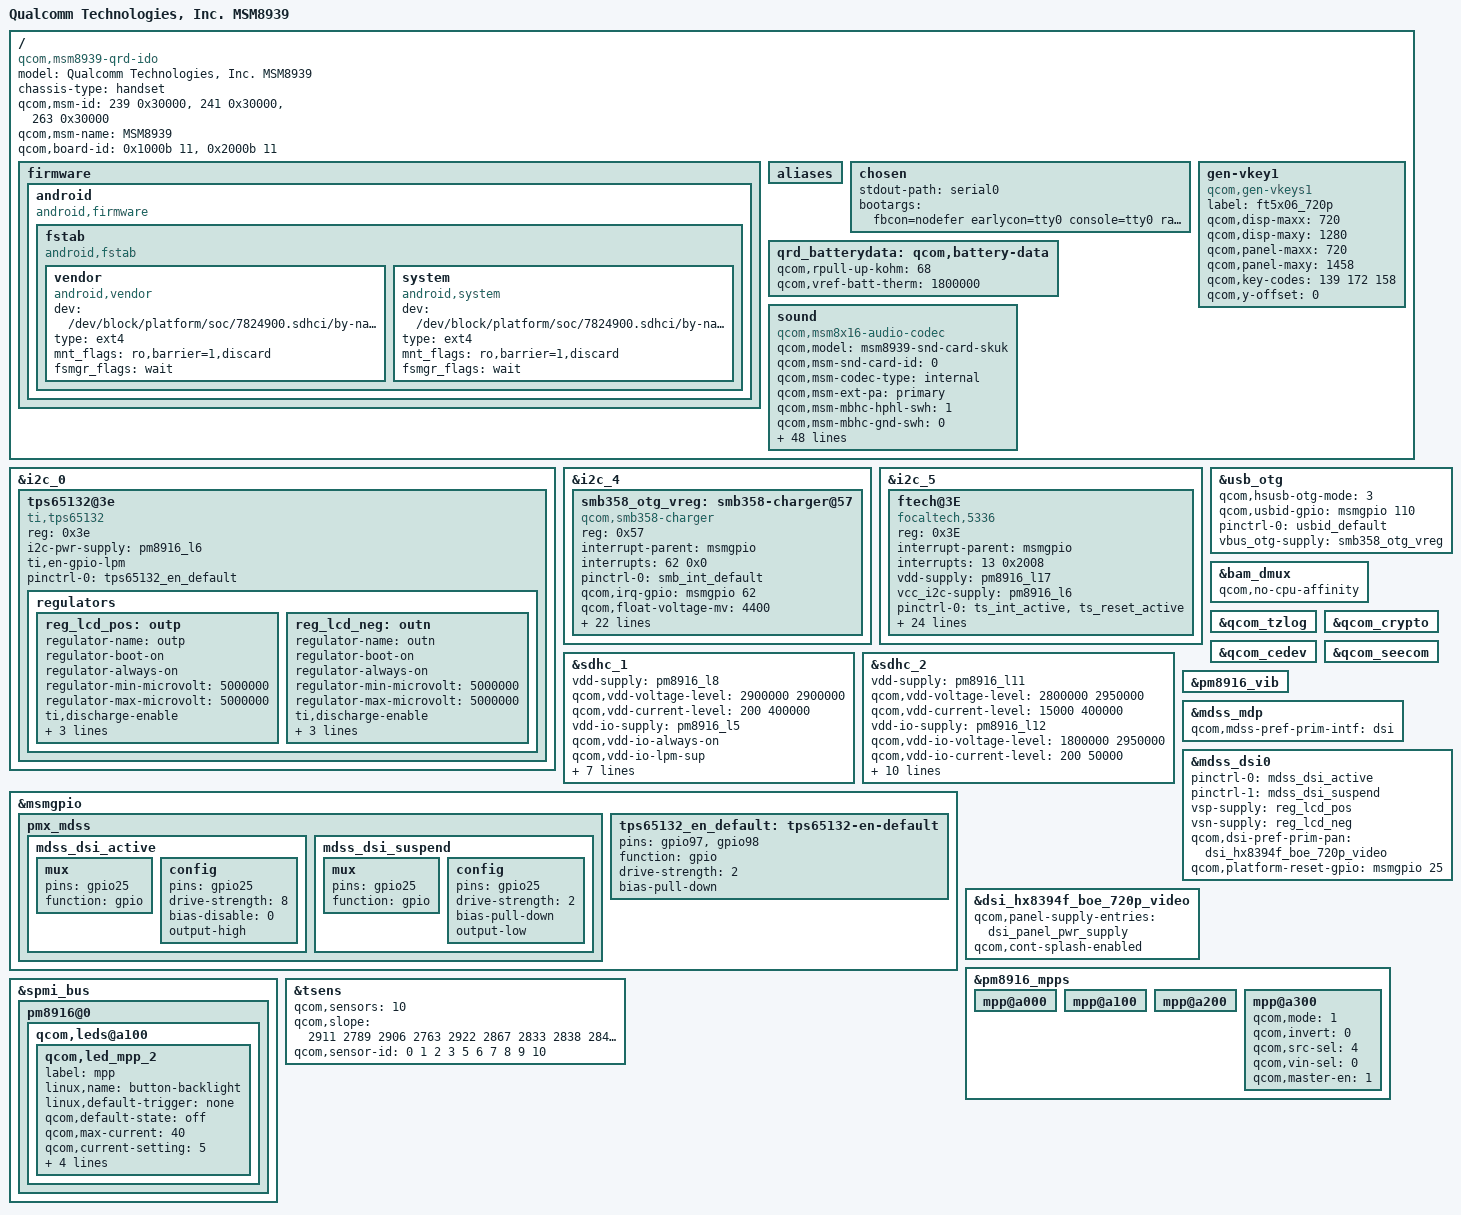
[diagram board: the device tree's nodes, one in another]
// SPDX-License-Identifier: GPL-2.0-only

/dts-v1/;
#include <dt-bindings/clock/msm-clocks-8936.h>
#include <dt-bindings/clock/msm-cpu-clocks-8939.h>
#include "msm8939.dtsi"
#include "msm8939-camera-sensor-qrd-ido.dtsi"
#include "dsi-panel-hx8394f-boe-720p-video.dtsi"
#include <dt-bindings/gpio/gpio.h>

/ {
	model = "Qualcomm Technologies, Inc. MSM8939";
	compatible = "qcom,msm8939-qrd-ido", "qcom,msm8939-qrd", "qcom,msm8939", "qcom,qrd";
	chassis-type = "handset";
	qcom,msm-id = <239 0x30000>, <241 0x30000>, <263 0x30000>;
	qcom,msm-name = "MSM8939";
	qcom,board-id = <0x1000b 11>, <0x2000b 11>;

       firmware: firmware {
                 android {
                         compatible = "android,firmware";
                         fstab {
                                 compatible = "android,fstab";
                                 vendor {
                                         compatible = "android,vendor";
                                         dev = "/dev/block/platform/soc/7824900.sdhci/by-name/vendor";
                                         type = "ext4";
                                         mnt_flags = "ro,barrier=1,discard";
                                         fsmgr_flags = "wait";
                                         status = "ok";
                                 };
                                 system {
                                         compatible = "android,system";
                                         dev = "/dev/block/platform/soc/7824900.sdhci/by-name/system";
                                        type = "ext4";
                                     mnt_flags = "ro,barrier=1,discard";
                                       fsmgr_flags = "wait";
                                      status = "ok";
                                 };
                        };
                };
       };

	aliases {
	};

	chosen {
		stdout-path = "serial0";
		bootargs = "fbcon=nodefer earlycon=tty0 console=tty0 ramoops.mem_address=0xdfe00000 ramoops.mem_size=0x00200000 ramoops.record_size=0x40000 ramoops.console_size=0x40000 ramoops.ftrace_size=0x10000 ramoops.pmsg_size=0x20000 ramoops.ecc=1";
		#address-cells = <2>;
		#size-cells = <2>;
		ranges;
#if 0
		framebuffer0: framebuffer@83003000 {
			status= "okay";
			compatible = "simple-framebuffer";
			reg = <0x0 0x83200000 0x0 0x2000000>;
			width = <720>;
			height = <1280>;
			stride = <(720 * 3)>;
			format = "r8g8b8";
		};
#endif
	};
#if 0
    reserved-memory {
		cont_splash_mem: framebuffer@83000000 {
			compatible = "removed-dma-pool";
			reg = <0x0 0x83000000 0x0 0x2000000>;
			no-map;
		};
	};
#endif

	qrd_batterydata: qcom,battery-data {
		qcom,rpull-up-kohm = <68>;
		qcom,vref-batt-therm = <1800000>;

		#include "batterydata-wingtech-xingwangda_ATL-4v4-4000mah.dtsi"
	};

	gen-vkey1 {
		compatible = "qcom,gen-vkeys1";
		label = "ft5x06_720p";
		qcom,disp-maxx = <720>;
		qcom,disp-maxy = <1280>;
		qcom,panel-maxx = <720>;
		qcom,panel-maxy = <1458>;
		qcom,key-codes = <139 172 158>;
		qcom,y-offset = <0>;
	};

	sound {
		compatible = "qcom,msm8x16-audio-codec";
		qcom,model = "msm8939-snd-card-skuk";
		qcom,msm-snd-card-id = <0>;
		qcom,msm-codec-type = "internal";
		qcom,msm-ext-pa = "primary";
		qcom,msm-mbhc-hphl-swh = <1>;
		qcom,msm-mbhc-gnd-swh = <0>;
		ext-spk-amp-gpio = <&msmgpio 121 0>;
		headset-gpio = <&msmgpio 8 0>;
		qcom,msm-micbias1-ext-cap;
		qcom,msm-hs-micbias-type = "internal";
		qcom,audio-routing =
			"RX_BIAS","MCLK",
			"SPK_RX_BIAS","MCLK",
			"INT_LDO_H","MCLK",
			"MIC BIAS External","Handset Mic",
			"MIC BIAS Internal2","Headset Mic",
			"MIC BIAS External","Secondary Mic",
			"AMIC1","MIC BIAS External",
			"AMIC2","MIC BIAS Internal2",
			"AMIC3","MIC BIAS External";
		pinctrl-names = "cdc_lines_act",
				"cdc_lines_sus";
		pinctrl-0 = <&cdc_pdm_lines_act>;
		pinctrl-1 = <&cdc_pdm_lines_sus>;
		asoc-platform = <&pcm0>,<&pcm1>,<&voip>,<&voice>,
				<&loopback>,<&compress>,<&hostless>,
				<&afe>,<&lsm>,<&routing>,<&lpa>;
		asoc-platform-names = "msm-pcm-dsp.0","msm-pcm-dsp.1",
				"msm-voip-dsp","msm-pcm-voice","msm-pcm-loopback",
				"msm-compress-dsp","msm-pcm-hostless","msm-pcm-afe",
				"msm-lsm-client","msm-pcm-routing","msm-pcm-lpa";
		asoc-cpu = <&dai_pri_auxpcm>,<&dai_hdmi>,<&dai_mi2s0>,<&dai_mi2s1>,
				<&dai_mi2s2>,<&dai_mi2s3>,<&sb_0_rx>,<&sb_0_tx>,
				<&sb_1_rx>,<&sb_1_tx>,<&sb_3_rx>,<&sb_3_tx>,
				<&sb_4_rx>,<&sb_4_tx>,<&sb_5_tx>,<&bt_sco_rx>,
				<&bt_sco_tx>,<&bt_a2dp_rx>,<&int_fm_rx>,<&int_fm_tx>,<&afe_pcm_rx>,
				<&afe_pcm_tx>,<&afe_proxy_rx>,<&afe_proxy_tx>,
				<&incall_record_rx>,<&incall_record_tx>,<&incall_music_rx>,
				<&incall_music_2_rx>;
		asoc-cpu-names = "msm-dai-q6-auxpcm.1","msm-dai-q6-hdmi.8","msm-dai-q6-mi2s.0",
				"msm-dai-q6-mi2s.1","msm-dai-q6-mi2s.2",
				"msm-dai-q6-mi2s.3","msm-dai-q6-dev.16384",
				"msm-dai-q6-dev.16385","msm-dai-q6-dev.16386",
				"msm-dai-q6-dev.16387","msm-dai-q6-dev.16390",
				"msm-dai-q6-dev.16391","msm-dai-q6-dev.16392",
				"msm-dai-q6-dev.16393","msm-dai-q6-dev.16395",
				"msm-dai-q6-dev.12288","msm-dai-q6-dev.12289",
                                "msm-dai-q6-dev.12290",
				"msm-dai-q6-dev.12292","msm-dai-q6-dev.12293",
				"msm-dai-q6-dev.224","msm-dai-q6-dev.225",
				"msm-dai-q6-dev.241","msm-dai-q6-dev.240",
				"msm-dai-q6-dev.32771","msm-dai-q6-dev.32772",
				"msm-dai-q6-dev.32773","msm-dai-q6-dev.32770";
		asoc-codec = <&stub_codec>,<&pm8916_tombak_dig>;
		asoc-codec-names = "msm-stub-codec.1","tombak_codec";
	};
};

&i2c_0 {/* BLSP1 QUP2 */
	tps65132@3e {
		compatible = "ti,tps65132";
		reg = <0x3e>;
		i2c-pwr-supply = <&pm8916_l6>;
		ti,en-gpio-lpm;
		pinctrl-names = "default";
		pinctrl-0 = <&tps65132_en_default>;
		regulators {
			reg_lcd_pos: outp {
				regulator-name = "outp";
				regulator-boot-on;
				regulator-always-on;
				regulator-min-microvolt = <5000000>;
				regulator-max-microvolt = <5000000>;
				ti,discharge-enable;
				ti,enable-time = <800>;
				ti,current-limit = <200000>;
				ti,en-gpio = <&msmgpio 97 0>;
			};

			reg_lcd_neg: outn {
				regulator-name = "outn";
				regulator-boot-on;
				regulator-always-on;
				regulator-min-microvolt = <5000000>;
				regulator-max-microvolt = <5000000>;
				ti,discharge-enable;
				ti,enable-time = <800>;
				ti,current-limit = <40000>;
				ti,en-gpio = <&msmgpio 98 0>;
			};
		};
	};
};

&i2c_4 {
#if 0
	smb358_otg_vreg: smb358-charger@57 {
	compatible = "qcom,smb358-charger";
	reg = <0x57>;
	interrupt-parent = <&msmgpio>;
	interrupts = <62 0x0>;
	pinctrl-names = "default";
	pinctrl-0 = <&smb_int_default>;
	qcom,irq-gpio = <&msmgpio 62 0x0>;
	qcom,float-voltage-mv = <4400>;
	qcom,recharge-mv = <50>;
	regulator-name = "smb358_otg_vreg";
	qcom,batt-id-vref-uv = <1800000>;
	qcom,batt-id-rpullup-kohm = <100>;
	qcom,fastchg-current-max-ma = <2000>;
	qcom,iterm-disabled;
	qcom,chg-vadc = <&pm8916_vadc>;
	qcom,chg-adc_tm = <&pm8916_adc_tm>;
	qcom,chg-inhibit-disabled;
	qcom,disable-apsd;
	status = "ok";
	};
#endif
#if 1
	smb358_otg_vreg: smb358-charger@57 {
	compatible = "qcom,smb358-charger";
	reg = <0x57>;
	interrupt-parent = <&msmgpio>;
	interrupts = <62 0x0>;
	pinctrl-names = "default";
	pinctrl-0 = <&smb_int_default>;
	qcom,irq-gpio = <&msmgpio 62 0x0>;
	qcom,float-voltage-mv = <4400>;
	qcom,recharge-mv = <50>;
	regulator-name = "smb358_otg_vreg";
	qcom,thermal-mitigation = <2000 1000 800 800>;
	qcom,fastchg-current-max-ma = <2000>;
	qcom,bms-psy-name = "bms";
	qcom,iterm-disabled;
	qcom,bms-controlled-charging;
	qcom,chg-inhibit-disabled;
	qcom,chg-vadc = <&pm8916_vadc>;
	qcom,chg-adc_tm = <&pm8916_adc_tm>;
	qcom,using-pmic-therm;
	qcom,bat-present-decidegc = <(300)>;
	qcom,disable-apsd;
/*
 * Below properties are used for enable JEITA
 */
	qcom,hot-bat-decidegc = <600>;
	qcom,warm-bat-decidegc = <450>;
	qcom,cool-bat-decidegc = <100>;
	qcom,cold-bat-decidegc = <0>;
	qcom,warm-bat-ma = <1500>;
	qcom,cool-bat-ma = <1000>;
	qcom,warm-bat-mv = <4100>;
	qcom,cool-bat-mv = <4350>;
	qcom,battery-fcc = <4000>;
	status = "ok";
	};
#endif
};

&i2c_5	{/* BLSP1 QUP5 */
		ftech@3E {
			compatible = "focaltech,5336";
			reg = <0x3E>;
			interrupt-parent = <&msmgpio>;
			interrupts = <13 0x2008>;
			vdd-supply = <&pm8916_l17>;
			vcc_i2c-supply = <&pm8916_l6>;
			/* pins used by touchscreen */
			pinctrl-names = "pmx_ts_active","pmx_ts_suspend";
			pinctrl-0 = <&ts_int_active &ts_reset_active>;
			pinctrl-1 = <&ts_int_suspend &ts_reset_suspend>;
			ftech,name = "ft5336";
			ftech,family-id = <0x36>;
			ftech,reset-gpio = <&msmgpio 12 0x0>;
			ftech,irq-gpio = <&msmgpio 13 0x2008>;
			ftech,display-coords = <0 0 720 1280>;
			ftech,panel-coords = <0 0 720 1280>;
			/*ftech,button-map= <139 102 158>;*/
			ftech,virtual-key1 = <139 180 2000>;/*menu*/
			ftech,virtual-key2 = <172 540 2000>;/*home*/
			ftech,virtual-key3 = <158 900 2000>;/*back*/
			ftech,no-force-update;
			ftech,i2c-pull-up;
			ftech,group-id = <1>;
			ftech,hard-reset-delay-ms = <20>;
			ftech,soft-reset-delay-ms = <200>;
			ftech,num-max-touches = <10>;
			ftech,fw-delay-aa-ms = <30>;
			ftech,fw-delay-55-ms = <30>;
			ftech,fw-upgrade-id1 = <0x79>;
			ftech,fw-upgrade-id2 = <0x18>;
			ftech,fw-delay-readid-ms = <10>;
			ftech,fw-delay-era-flsh-ms = <2000>;
			ftech,fw-auto-cal;
			ftech,ignore-id-check;
		};
	};

&sdhc_1 {
	vdd-supply = <&pm8916_l8>;
	qcom,vdd-voltage-level = <2900000 2900000>;
	qcom,vdd-current-level = <200 400000>;

	vdd-io-supply = <&pm8916_l5>;
	qcom,vdd-io-always-on;
	qcom,vdd-io-lpm-sup;
	qcom,vdd-io-voltage-level = <1800000 1800000>;
	qcom,vdd-io-current-level = <200 60000>;

	pinctrl-names = "active", "sleep";
	pinctrl-0 = <&sdc1_clk_on &sdc1_cmd_on &sdc1_data_on>;
	pinctrl-1 = <&sdc1_clk_off &sdc1_cmd_off &sdc1_data_off>;

	qcom,nonremovable;

	status = "okay";
};

&sdhc_2 {
	vdd-supply = <&pm8916_l11>;
	qcom,vdd-voltage-level = <2800000 2950000>;
	qcom,vdd-current-level = <15000 400000>;

	vdd-io-supply = <&pm8916_l12>;
	qcom,vdd-io-voltage-level = <1800000 2950000>;
	qcom,vdd-io-current-level = <200 50000>;

	pinctrl-names = "active", "sleep";
	pinctrl-0 = <&sdc2_clk_on &sdc2_cmd_on &sdc2_data_on &sdc2_cd_on>;
	pinctrl-1 = <&sdc2_clk_off &sdc2_cmd_off &sdc2_data_off &sdc2_cd_off>;

	#address-cells = <0>;
	interrupt-parent = <&sdhc_2>;
	interrupts = <0 1 2>;
	#interrupt-cells = <1>;
	interrupt-map-mask = <0xffffffff>;
	interrupt-map = <0 &intc 0 125 0
			1 &intc 0 221 0
			2 &msmgpio 38 0>;
	interrupt-names = "hc_irq", "pwr_irq", "status_irq";
	cd-gpios = <&msmgpio 38 0x1>;

	status = "okay";
};

#if 1
&usb_otg {
	   qcom,hsusb-otg-mode = <3>;
	   qcom,usbid-gpio = <&msmgpio 110 0>;
	   pinctrl-names = "default";
	   pinctrl-0 = <&usbid_default>;
	   vbus_otg-supply = <&smb358_otg_vreg>;
};
#endif

&bam_dmux {
	qcom,no-cpu-affinity;
};

&qcom_tzlog {
	status = "okay";
};

&qcom_crypto {
	status = "okay";
};

&qcom_cedev {
	status = "okay";
};

&qcom_seecom {
	status = "okay";
};

&pm8916_vib{
	status = "okay";
};

&mdss_mdp {
	qcom,mdss-pref-prim-intf = "dsi";
};

&msmgpio {
	pmx_mdss {
		mdss_dsi_active: mdss_dsi_active {
			mux {
				pins = "gpio25";
				function = "gpio";
			};
			config {
				pins = "gpio25";
				drive-strength = <8>; /* 8 mA */
				bias-disable = <0>; /* no pull */
				output-high;
			};
		};

		mdss_dsi_suspend: mdss_dsi_suspend {
			mux {
				pins = "gpio25";
				function = "gpio";
                        };
			config {
				pins = "gpio25";
				drive-strength = <2>; /* 2 mA */
				bias-pull-down; /* pull down */
				output-low;
			};
		};
	};

    tps65132_en_default: tps65132-en-default {
		pins = "gpio97", "gpio98";
		function = "gpio";

		drive-strength = <2>;
		bias-pull-down;
	};

};

&mdss_dsi0 {
	pinctrl-names = "mdss_default", "mdss_sleep";
	pinctrl-0 = <&mdss_dsi_active>;
	pinctrl-1 = <&mdss_dsi_suspend>;
	vsp-supply = <&reg_lcd_pos>;
	vsn-supply = <&reg_lcd_neg>;
	qcom,dsi-pref-prim-pan = <&dsi_hx8394f_boe_720p_video>;
	qcom,platform-reset-gpio = <&msmgpio 25 0>;

	/delete-node/ qcom,ctrl-supply-entry@0;
};

&dsi_hx8394f_boe_720p_video {
	qcom,panel-supply-entries = <&dsi_panel_pwr_supply>;
	qcom,cont-splash-enabled;
};

&pm8916_mpps {
	mpp@a000 { /* MPP 1 */
		/* VDD_PX */
		status = "okay";
	};

	mpp@a100 { /* MPP 2 */
		/* HR LED */
		status = "okay";
	};

	mpp@a200 { /* MPP 3 */
		/* VREF DAC */
		status = "okay";
	};

	mpp@a300 { /* MPP 4 */
		/* Backlight PWM */
		qcom,mode = <1>;		/* Digital output */
		qcom,invert = <0>;		/* Disable invert */
		qcom,src-sel = <4>;		/* DTEST1 */
		qcom,vin-sel = <0>;		/* VPH_PWR */
		qcom,master-en = <1>;		/* Enable MPP */
		status = "okay";
	};
};

&spmi_bus {
	pm8916@0 {
		qcom,leds@a100 {
			status = "okay";
			qcom,led_mpp_2 {
				label = "mpp";
				linux,name = "button-backlight";
				linux,default-trigger = "none";
				qcom,default-state = "off";
				qcom,max-current = <40>;
				qcom,current-setting = <5>;
				qcom,id = <6>;
				qcom,mode = "manual";
				qcom,source-sel = <1>;
				qcom,mode-ctrl = <0x60>;
			};
		};
	};
};

&tsens {
	qcom,sensors = <10>;
	qcom,slope = <2911 2789 2906 2763 2922 2867 2833 2838 2840 2852>;
	qcom,sensor-id = <0 1 2 3 5 6 7 8 9 10>;
};

&firmware {
	android {
		fstab {
			vendor {
				dev = "/dev/block/platform/soc/7824900.sdhci/by-name/cust";
			};
		};
	};
};

